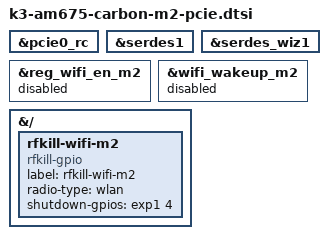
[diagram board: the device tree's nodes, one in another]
// SPDX-License-Identifier: GPL-2.0
/*
 * M.2 PCIE Wi-Fi common functions
 *
 * Copyright (C) 2025 Ezurio LLC
 */

#define M2_PCIE

#include "k3-am675-carbon-m2.dtsi"

&pcie0_rc {
	status = "okay";
};

&serdes1 {
	status = "okay";
};

&serdes_wiz1 {
	status = "okay";
};

&reg_wifi_en_m2 {
	status = "disabled";
};

&wifi_wakeup_m2 {
	status = "disabled";
};

&{/} {
	rfkill-wifi-m2 {
		compatible = "rfkill-gpio";
		label = "rfkill-wifi-m2";
		radio-type = "wlan";
		shutdown-gpios = <&exp1 4 GPIO_ACTIVE_HIGH>;
	};
};
